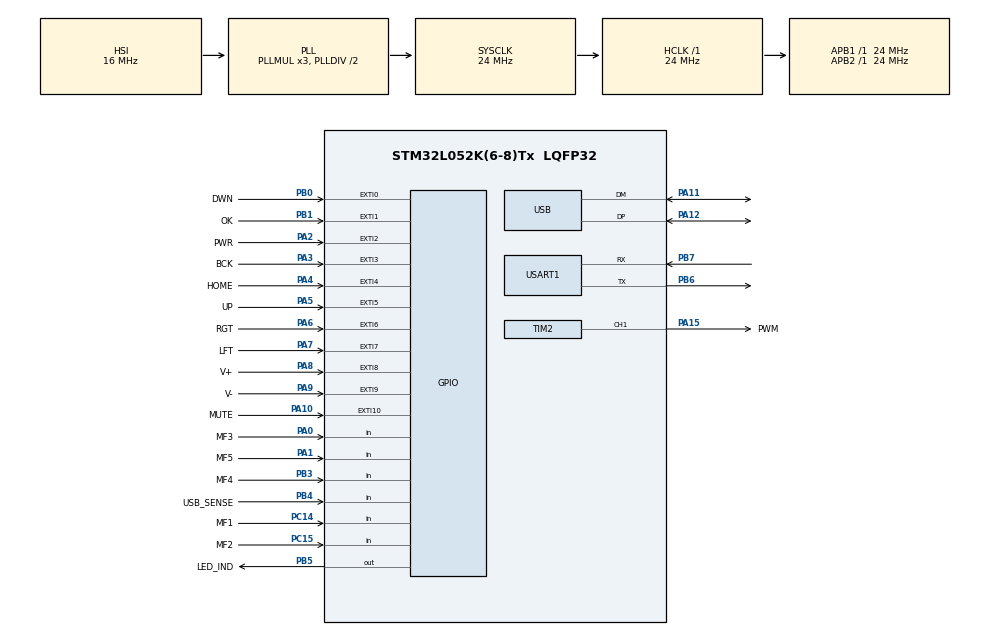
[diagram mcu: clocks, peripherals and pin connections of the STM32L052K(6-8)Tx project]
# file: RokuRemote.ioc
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Mcu.Family=STM32L0
Mcu.Name=STM32L052K(6-8)Tx
Mcu.Package=LQFP32
NVIC.EXTI0_1_IRQn=true\:0\:0\:false\:false\:true\:true\:true
NVIC.EXTI2_3_IRQn=true\:0\:0\:false\:false\:true\:true\:true
NVIC.EXTI4_15_IRQn=true\:0\:0\:false\:false\:true\:true\:true
NVIC.USB_IRQn=true\:0\:0\:false\:false\:true\:false\:true
PA0.GPIO_Label=MF3
PA0.GPIO_PuPd=GPIO_PULLDOWN
PA0.Signal=GPIO_Input
PA1.GPIO_Label=MF5
PA1.GPIO_PuPd=GPIO_PULLDOWN
PA1.Signal=GPIO_Input
PA10.GPIO_Label=MUTE
PA10.GPIO_PuPd=GPIO_PULLDOWN
PA10.Signal=GPXTI10
PA11.Mode=Device
PA11.Signal=USB_DM
PA12.Mode=Device
PA12.Signal=USB_DP
PA13.Mode=Serial_Wire
PA13.Signal=SYS_SWDIO
PA14.Mode=Serial_Wire
PA14.Signal=SYS_SWCLK
PA15.GPIO_Label=PWM
PA15.Signal=S_TIM2_CH1
PA2.GPIO_Label=PWR
PA2.GPIO_ModeDefaultEXTI=GPIO_MODE_IT_RISING
PA2.GPIO_PuPd=GPIO_PULLDOWN
PA2.Signal=GPXTI2
PA3.GPIO_Label=BCK
PA3.GPIO_PuPd=GPIO_PULLDOWN
PA3.Signal=GPXTI3
PA4.GPIO_Label=HOME
PA4.GPIO_PuPd=GPIO_PULLDOWN
PA4.Signal=GPXTI4
PA5.GPIO_Label=UP
PA5.GPIO_PuPd=GPIO_PULLDOWN
PA5.Signal=GPXTI5
PA6.GPIO_Label=RGT
PA6.GPIO_PuPd=GPIO_PULLDOWN
PA6.Signal=GPXTI6
PA7.GPIO_Label=LFT
PA7.GPIO_PuPd=GPIO_PULLDOWN
PA7.Signal=GPXTI7
PA8.GPIO_Label=V+
PA8.GPIO_PuPd=GPIO_PULLDOWN
PA8.Signal=GPXTI8
PA9.GPIO_Label=V-
PA9.GPIO_PuPd=GPIO_PULLDOWN
PA9.Signal=GPXTI9
PB0.GPIO_Label=DWN
PB0.GPIO_PuPd=GPIO_PULLDOWN
PB0.Signal=GPXTI0
PB1.GPIO_Label=OK
PB1.GPIO_PuPd=GPIO_PULLDOWN
PB1.Signal=GPXTI1
PB3.GPIO_Label=MF4
PB3.GPIO_PuPd=GPIO_PULLDOWN
PB3.Signal=GPIO_Input
PB4.GPIO_Label=USB_SENSE
PB4.GPIO_PuPd=GPIO_PULLDOWN
PB4.Signal=GPIO_Input
PB5.GPIO_Label=LED_IND
PB5.GPIO_PuPd=GPIO_PULLDOWN
PB5.Signal=GPIO_Output
PB6.Mode=Asynchronous
PB6.Signal=USART1_TX
PB7.Mode=Asynchronous
PB7.Signal=USART1_RX
PC14-OSC32_IN.GPIO_Label=MF1
PC14-OSC32_IN.GPIO_PuPd=GPIO_PULLDOWN
PC14-OSC32_IN.Signal=GPIO_Input
PC15-OSC32_OUT.GPIO_Label=MF2
PC15-OSC32_OUT.GPIO_PuPd=GPIO_PULLDOWN
PC15-OSC32_OUT.Signal=GPIO_Input
ProjectManager.HeapSize=0x200
ProjectManager.StackSize=0x400
ProjectManager.TargetToolchain=STM32CubeIDE
RCC.ADCFreq_Value=16000000
RCC.AHBFreq_Value=24000000
RCC.APB1Freq_Value=24000000
RCC.APB1TimFreq_Value=24000000
RCC.APB2Freq_Value=24000000
RCC.APB2TimFreq_Value=24000000
RCC.HCLKFreq_Value=24000000
RCC.HSI16_VALUE=16000000
RCC.HSI48MClockSelection=RCC_USBCLKSOURCE_HSI48
RCC.HSI48_VALUE=48000000
RCC.HSI_VALUE=16000000
RCC.LSE_VALUE=32768
RCC.MSI_VALUE=2097000
RCC.SYSCLKFreq_VALUE=24000000
RCC.SYSCLKSource=RCC_SYSCLKSOURCE_PLLCLK
RCC.VCOOutputFreq_Value=48000000
SH.S_TIM2_CH1.0=TIM2_CH1,PWM Generation1 CH1
TIM2.Channel-PWM\ Generation1\ CH1=TIM_CHANNEL_1
TIM2.Period=126
TIM2.Prescaler=4
TIM2.Pulse-PWM\ Generation1\ CH1=38
TIM6.Period=500
TIM6.Prescaler=24
USART1.VirtualMode-Asynchronous=VM_ASYNC
USB_DEVICE.CLASS_NAME_FS=CDC
USB_DEVICE.VirtualMode=Cdc
USB_DEVICE.VirtualModeFS=Cdc_FS
VP_RTC_VS_RTC_Activate.Mode=RTC_Enabled
VP_RTC_VS_RTC_Calendar.Mode=RTC_Calendar
VP_TIM2_VS_ClockSourceINT.Mode=Internal
VP_TIM6_VS_ClockSourceINT.Mode=Enable_Timer
VP_TIM6_VS_OPM.Mode=OPM_bit
VP_USB_DEVICE_VS_USB_DEVICE_CDC_FS.Mode=CDC_FS
board=custom

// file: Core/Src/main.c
/* USER CODE BEGIN Header */
/**
  ******************************************************************************
  * @file           : main.c
  * @brief          : Main program body
  ******************************************************************************
  * @attention
  *
  * <h2><center>&copy; Copyright (c) 2020 STMicroelectronics.
  * All rights reserved.</center></h2>
  *
  * This software component is licensed by ST under BSD 3-Clause license,
  * the "License"; You may not use this file except in compliance with the
  * License. You may obtain a copy of the License at:
  *                        opensource.org/licenses/BSD-3-Clause
  *
  ******************************************************************************
  */
/* USER CODE END Header */

#include "main.h"
#include "usb_device.h"

/* USER CODE BEGIN Includes */
#include <stdbool.h>
#include "Remote.h"
/* USER CODE END Includes */

RTC_HandleTypeDef hrtc;

TIM_HandleTypeDef htim2;
TIM_HandleTypeDef htim6;

UART_HandleTypeDef huart1;

void SystemClock_Config(void);
static void MX_GPIO_Init(void);
static void MX_RTC_Init(void);
static void MX_TIM2_Init(void);
static void MX_USART1_UART_Init(void);
static void MX_TIM6_Init(void);

int main(void)
{

  /* MCU Configuration--------------------------------------------------------*/

  /* Reset of all peripherals, Initializes the Flash interface and the Systick. */
  HAL_Init();

  /* Configure the system clock */
  SystemClock_Config();

  /* Initialize all configured peripherals */
  MX_GPIO_Init();
  MX_RTC_Init();
  MX_TIM2_Init();
  MX_USB_DEVICE_Init();
  MX_USART1_UART_Init();
  MX_TIM6_Init();

  /* Infinite loop */
  /* USER CODE BEGIN WHILE */
  sendData(0x57e3f00f);
  while (1)
  {
	  HAL_GPIO_TogglePin(GPIOB, LED_IND_Pin);
	  HAL_Delay(1000);

    /* USER CODE END WHILE */

  }
}

void SystemClock_Config(void)
{
  RCC_OscInitTypeDef RCC_OscInitStruct = {0};
  RCC_ClkInitTypeDef RCC_ClkInitStruct = {0};
  RCC_PeriphCLKInitTypeDef PeriphClkInit = {0};

  /** Configure the main internal regulator output voltage
  */
  __HAL_PWR_VOLTAGESCALING_CONFIG(PWR_REGULATOR_VOLTAGE_SCALE1);
  /** Initializes the CPU, AHB and APB busses clocks
  */
  RCC_OscInitStruct.OscillatorType = RCC_OSCILLATORTYPE_HSI|RCC_OSCILLATORTYPE_LSI
                              |RCC_OSCILLATORTYPE_HSI48;
  RCC_OscInitStruct.HSIState = RCC_HSI_ON;
  RCC_OscInitStruct.HSICalibrationValue = RCC_HSICALIBRATION_DEFAULT;
  RCC_OscInitStruct.LSIState = RCC_LSI_ON;
  RCC_OscInitStruct.HSI48State = RCC_HSI48_ON;
  RCC_OscInitStruct.PLL.PLLState = RCC_PLL_ON;
  RCC_OscInitStruct.PLL.PLLSource = RCC_PLLSOURCE_HSI;
  RCC_OscInitStruct.PLL.PLLMUL = RCC_PLLMUL_3;
  RCC_OscInitStruct.PLL.PLLDIV = RCC_PLLDIV_2;
  if (HAL_RCC_OscConfig(&RCC_OscInitStruct) != HAL_OK)
  {
    Error_Handler();
  }
  /** Initializes the CPU, AHB and APB busses clocks
  */
  RCC_ClkInitStruct.ClockType = RCC_CLOCKTYPE_HCLK|RCC_CLOCKTYPE_SYSCLK
                              |RCC_CLOCKTYPE_PCLK1|RCC_CLOCKTYPE_PCLK2;
  RCC_ClkInitStruct.SYSCLKSource = RCC_SYSCLKSOURCE_PLLCLK;
  RCC_ClkInitStruct.AHBCLKDivider = RCC_SYSCLK_DIV1;
  RCC_ClkInitStruct.APB1CLKDivider = RCC_HCLK_DIV1;
  RCC_ClkInitStruct.APB2CLKDivider = RCC_HCLK_DIV1;

  if (HAL_RCC_ClockConfig(&RCC_ClkInitStruct, FLASH_LATENCY_1) != HAL_OK)
  {
    Error_Handler();
  }
  PeriphClkInit.PeriphClockSelection = RCC_PERIPHCLK_USART1|RCC_PERIPHCLK_RTC
                              |RCC_PERIPHCLK_USB;
  PeriphClkInit.Usart1ClockSelection = RCC_USART1CLKSOURCE_PCLK2;
  PeriphClkInit.RTCClockSelection = RCC_RTCCLKSOURCE_LSI;
  PeriphClkInit.UsbClockSelection = RCC_USBCLKSOURCE_HSI48;
  if (HAL_RCCEx_PeriphCLKConfig(&PeriphClkInit) != HAL_OK)
  {
    Error_Handler();
  }
}

static void MX_RTC_Init(void)
{

  RTC_TimeTypeDef sTime = {0};
  RTC_DateTypeDef sDate = {0};

  /** Initialize RTC Only
  */
  hrtc.Instance = RTC;
  hrtc.Init.HourFormat = RTC_HOURFORMAT_24;
  hrtc.Init.AsynchPrediv = 127;
  hrtc.Init.SynchPrediv = 255;
  hrtc.Init.OutPut = RTC_OUTPUT_DISABLE;
  hrtc.Init.OutPutRemap = RTC_OUTPUT_REMAP_NONE;
  hrtc.Init.OutPutPolarity = RTC_OUTPUT_POLARITY_HIGH;
  hrtc.Init.OutPutType = RTC_OUTPUT_TYPE_OPENDRAIN;
  if (HAL_RTC_Init(&hrtc) != HAL_OK)
  {
    Error_Handler();
  }

  /** Initialize RTC and set the Time and Date
  */
  sTime.Hours = 0x0;
  sTime.Minutes = 0x0;
  sTime.Seconds = 0x0;
  sTime.DayLightSaving = RTC_DAYLIGHTSAVING_NONE;
  sTime.StoreOperation = RTC_STOREOPERATION_RESET;
  if (HAL_RTC_SetTime(&hrtc, &sTime, RTC_FORMAT_BCD) != HAL_OK)
  {
    Error_Handler();
  }
  sDate.WeekDay = RTC_WEEKDAY_MONDAY;
  sDate.Month = RTC_MONTH_JANUARY;
  sDate.Date = 0x1;
  sDate.Year = 0x0;

  if (HAL_RTC_SetDate(&hrtc, &sDate, RTC_FORMAT_BCD) != HAL_OK)
  {
    Error_Handler();
  }

}

static void MX_TIM2_Init(void)
{

  TIM_ClockConfigTypeDef sClockSourceConfig = {0};
  TIM_MasterConfigTypeDef sMasterConfig = {0};
  TIM_OC_InitTypeDef sConfigOC = {0};

  htim2.Instance = TIM2;
  htim2.Init.Prescaler = 4;
  htim2.Init.CounterMode = TIM_COUNTERMODE_UP;
  htim2.Init.Period = 126;
  htim2.Init.ClockDivision = TIM_CLOCKDIVISION_DIV1;
  htim2.Init.AutoReloadPreload = TIM_AUTORELOAD_PRELOAD_DISABLE;
  if (HAL_TIM_Base_Init(&htim2) != HAL_OK)
  {
    Error_Handler();
  }
  sClockSourceConfig.ClockSource = TIM_CLOCKSOURCE_INTERNAL;
  if (HAL_TIM_ConfigClockSource(&htim2, &sClockSourceConfig) != HAL_OK)
  {
    Error_Handler();
  }
  if (HAL_TIM_PWM_Init(&htim2) != HAL_OK)
  {
    Error_Handler();
  }
  sMasterConfig.MasterOutputTrigger = TIM_TRGO_RESET;
  sMasterConfig.MasterSlaveMode = TIM_MASTERSLAVEMODE_DISABLE;
  if (HAL_TIMEx_MasterConfigSynchronization(&htim2, &sMasterConfig) != HAL_OK)
  {
    Error_Handler();
  }
  sConfigOC.OCMode = TIM_OCMODE_PWM1;
  sConfigOC.Pulse = 38;
  sConfigOC.OCPolarity = TIM_OCPOLARITY_HIGH;
  sConfigOC.OCFastMode = TIM_OCFAST_DISABLE;
  if (HAL_TIM_PWM_ConfigChannel(&htim2, &sConfigOC, TIM_CHANNEL_1) != HAL_OK)
  {
    Error_Handler();
  }
  HAL_TIM_MspPostInit(&htim2);

}

static void MX_TIM6_Init(void)
{

  TIM_MasterConfigTypeDef sMasterConfig = {0};

  htim6.Instance = TIM6;
  htim6.Init.Prescaler = 24;
  htim6.Init.CounterMode = TIM_COUNTERMODE_UP;
  htim6.Init.Period = 500;
  htim6.Init.AutoReloadPreload = TIM_AUTORELOAD_PRELOAD_DISABLE;
  if (HAL_TIM_Base_Init(&htim6) != HAL_OK)
  {
    Error_Handler();
  }
  if (HAL_TIM_OnePulse_Init(&htim6, TIM_OPMODE_SINGLE) != HAL_OK)
  {
    Error_Handler();
  }
  sMasterConfig.MasterOutputTrigger = TIM_TRGO_RESET;
  sMasterConfig.MasterSlaveMode = TIM_MASTERSLAVEMODE_DISABLE;
  if (HAL_TIMEx_MasterConfigSynchronization(&htim6, &sMasterConfig) != HAL_OK)
  {
    Error_Handler();
  }

}

static void MX_USART1_UART_Init(void)
{

  huart1.Instance = USART1;
  huart1.Init.BaudRate = 115200;
  huart1.Init.WordLength = UART_WORDLENGTH_8B;
  huart1.Init.StopBits = UART_STOPBITS_1;
  huart1.Init.Parity = UART_PARITY_NONE;
  huart1.Init.Mode = UART_MODE_TX_RX;
  huart1.Init.HwFlowCtl = UART_HWCONTROL_NONE;
  huart1.Init.OverSampling = UART_OVERSAMPLING_16;
  huart1.Init.OneBitSampling = UART_ONE_BIT_SAMPLE_DISABLE;
  huart1.AdvancedInit.AdvFeatureInit = UART_ADVFEATURE_NO_INIT;
  if (HAL_UART_Init(&huart1) != HAL_OK)
  {
    Error_Handler();
  }

}

static void MX_GPIO_Init(void)
{
  GPIO_InitTypeDef GPIO_InitStruct = {0};

  /* GPIO Ports Clock Enable */
  __HAL_RCC_GPIOC_CLK_ENABLE();
  __HAL_RCC_GPIOA_CLK_ENABLE();
  __HAL_RCC_GPIOB_CLK_ENABLE();

  /*Configure GPIO pin Output Level */
  HAL_GPIO_WritePin(LED_IND_GPIO_Port, LED_IND_Pin, GPIO_PIN_RESET);

  /*Configure GPIO pins : MF1_Pin MF2_Pin */
  GPIO_InitStruct.Pin = MF1_Pin|MF2_Pin;
  GPIO_InitStruct.Mode = GPIO_MODE_INPUT;
  GPIO_InitStruct.Pull = GPIO_PULLDOWN;
  HAL_GPIO_Init(GPIOC, &GPIO_InitStruct);

  /*Configure GPIO pins : MF3_Pin MF5_Pin */
  GPIO_InitStruct.Pin = MF3_Pin|MF5_Pin;
  GPIO_InitStruct.Mode = GPIO_MODE_INPUT;
  GPIO_InitStruct.Pull = GPIO_PULLDOWN;
  HAL_GPIO_Init(GPIOA, &GPIO_InitStruct);

  /*Configure GPIO pins : PWR_Pin BCK_Pin HOME_Pin UP_Pin
                           RGT_Pin LFT_Pin V__Pin V_A9_Pin
                           MUTE_Pin */
  GPIO_InitStruct.Pin = PWR_Pin|BCK_Pin|HOME_Pin|UP_Pin
                          |RGT_Pin|LFT_Pin|V__Pin|V_A9_Pin
                          |MUTE_Pin;
  GPIO_InitStruct.Mode = GPIO_MODE_IT_RISING;
  GPIO_InitStruct.Pull = GPIO_PULLDOWN;
  HAL_GPIO_Init(GPIOA, &GPIO_InitStruct);

  /*Configure GPIO pins : DWN_Pin OK_Pin */
  GPIO_InitStruct.Pin = DWN_Pin|OK_Pin;
  GPIO_InitStruct.Mode = GPIO_MODE_IT_RISING;
  GPIO_InitStruct.Pull = GPIO_PULLDOWN;
  HAL_GPIO_Init(GPIOB, &GPIO_InitStruct);

  /*Configure GPIO pins : MF4_Pin USB_SENSE_Pin */
  GPIO_InitStruct.Pin = MF4_Pin|USB_SENSE_Pin;
  GPIO_InitStruct.Mode = GPIO_MODE_INPUT;
  GPIO_InitStruct.Pull = GPIO_PULLDOWN;
  HAL_GPIO_Init(GPIOB, &GPIO_InitStruct);

  /*Configure GPIO pin : LED_IND_Pin */
  GPIO_InitStruct.Pin = LED_IND_Pin;
  GPIO_InitStruct.Mode = GPIO_MODE_OUTPUT_PP;
  GPIO_InitStruct.Pull = GPIO_PULLDOWN;
  GPIO_InitStruct.Speed = GPIO_SPEED_FREQ_LOW;
  HAL_GPIO_Init(LED_IND_GPIO_Port, &GPIO_InitStruct);

  /* EXTI interrupt init*/
  HAL_NVIC_SetPriority(EXTI0_1_IRQn, 0, 0);
  HAL_NVIC_EnableIRQ(EXTI0_1_IRQn);

  HAL_NVIC_SetPriority(EXTI2_3_IRQn, 0, 0);
  HAL_NVIC_EnableIRQ(EXTI2_3_IRQn);

  HAL_NVIC_SetPriority(EXTI4_15_IRQn, 0, 0);
  HAL_NVIC_EnableIRQ(EXTI4_15_IRQn);

}

void Error_Handler(void)
{
}

/************************ (C) COPYRIGHT STMicroelectronics *****END OF FILE****/
